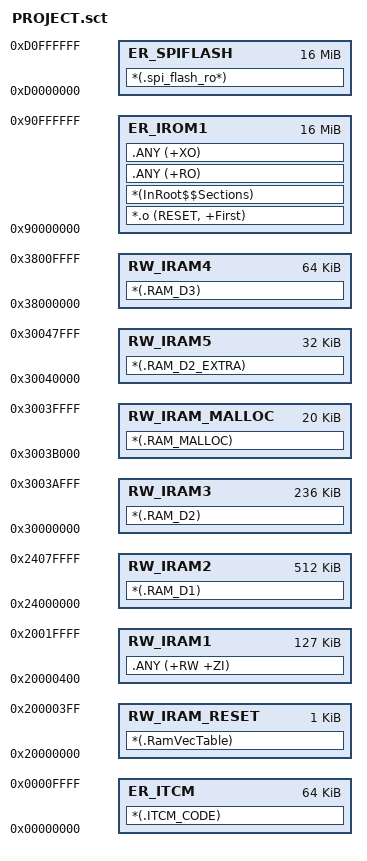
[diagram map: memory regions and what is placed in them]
; *************************************************************
; *** Scatter-Loading Description File generated by uVision ***
; *************************************************************

;LR_IROM1 0x08000000 0x00200000  {    ; load region size_region
;  ER_IROM1 0x08000000 0x00200000  {  ; load address = execution address
;   *.o (RESET, +First)
;   *(InRoot$$Sections)
;   .ANY (+RO)
;   .ANY (+XO)
;  }
;  
;  ; ITCM紧密耦合型指令缓存，可以运行精炼的程序，这里可以把中断服务函数和一些性能高要求代码定义到这个节区
;     ER_ITCM 0x00000000 0x00010000
;    {
;        *(.ITCM_CODE)
;    }
;  
;  ; RW data - 1KB DTCM - 专门给出1KB空间用于存储中断向量表，其实它实际大小是0x298，这里是跟着安富莱搞就固定0x400大小了。
;	RW_IRAM_RESET 0x20000000 0x00000400 {
;	*(.RamVecTable)   ; 自定义段，专门给中断向量表用，其他程序绝不可以用
;	}
;  
;  ; RW data - 127KB DTCM - 剩下127KB的DTCM用于主RAM运行程序。
;	RW_IRAM1 0x20000400 0x1FC00 {
;	.ANY (+RW +ZI)
;	}
;	
;	; RW data - 512KB AXI SRAM
;	RW_IRAM2 0x24000000 0x00080000 {
;	*(.RAM_D1)
;	}
;	
;	; SRAM1 + SRAM2 前段（236KB）
;    RW_IRAM3 0x30000000 0x0003B000 {
;    *(.RAM_D2)
;	}
;	
;    ; SRAM2_LAST（20KB）用于 malloc
;	; RW data - 20KB SRAM2_LAST(0x3003B000)
;	RW_IRAM_MALLOC 0x3003B000 0x5000 {
;	*(.RAM_MALLOC)
;	}
;                
;	; SRAM3（32KB）独立使用，用于USB和以太网缓冲区
;	RW_IRAM5 0x30040000 0x00008000 {
;	*(.RAM_D2_EXTRA)
;	}
;	
;	; RW data - 64KB SRAM4(0x38000000)
;	RW_IRAM4 0x38000000 0x00010000 {
;	*(.RAM_D3)
;	}
;}

LR_IROM1 0x90000000 0x01000000  {    ; load region size_region
  ER_IROM1 0x90000000 0x01000000  {  ; load address = execution address
   *.o (RESET, +First)
   *(InRoot$$Sections)
   .ANY (+RO)
   .ANY (+XO)
  }
  
  ; ITCM紧密耦合型指令缓存，可以运行精炼的程序，这里可以把中断服务函数和一些性能高要求代码定义到这个节区
     ER_ITCM 0x00000000 0x00010000
    {
        *(.ITCM_CODE)
    }
  
  ; RW data - 1KB DTCM - 专门给出1KB空间用于存储中断向量表，其实它实际大小是0x298，这里是跟着安富莱搞就固定0x400大小了。
	RW_IRAM_RESET 0x20000000 0x00000400 {
	*(.RamVecTable)   ; 自定义段，专门给中断向量表用，其他程序绝不可以用
	}
  
  ; RW data - 127KB DTCM - 剩下127KB的DTCM用于主RAM运行程序。
	RW_IRAM1 0x20000400 0x1FC00 {
	.ANY (+RW +ZI)
	}
	
	; RW data - 512KB AXI SRAM
	RW_IRAM2 0x24000000 0x00080000 {
	*(.RAM_D1)
	}
	
	; SRAM1 + SRAM2 前段（236KB）
    RW_IRAM3 0x30000000 0x0003B000 {
    *(.RAM_D2)
	}
	
    ; SRAM2_LAST（20KB）用于 malloc
	; RW data - 20KB SRAM2_LAST(0x3003B000)
	RW_IRAM_MALLOC 0x3003B000 0x5000 {
	*(.RAM_MALLOC)
	}
                
	; SRAM3（32KB）独立使用，用于USB和以太网缓冲区
	RW_IRAM5 0x30040000 0x00008000 {
	*(.RAM_D2_EXTRA)
	}
	
	; RW data - 64KB SRAM4(0x38000000)
	RW_IRAM4 0x38000000 0x00010000 {
	*(.RAM_D3)
	}
}

; ========== 新增：SPI Flash 字库存储区 ==========
LR_SPIFLASH 0xD0000000 0x01000000  {  ; 逻辑地址16MB，但是不可访问哦，只允许下载
  ER_SPIFLASH 0xD0000000 0x01000000  {
    *(.spi_flash_ro*)   ; 专门用于字库的自定义段
  }
}
